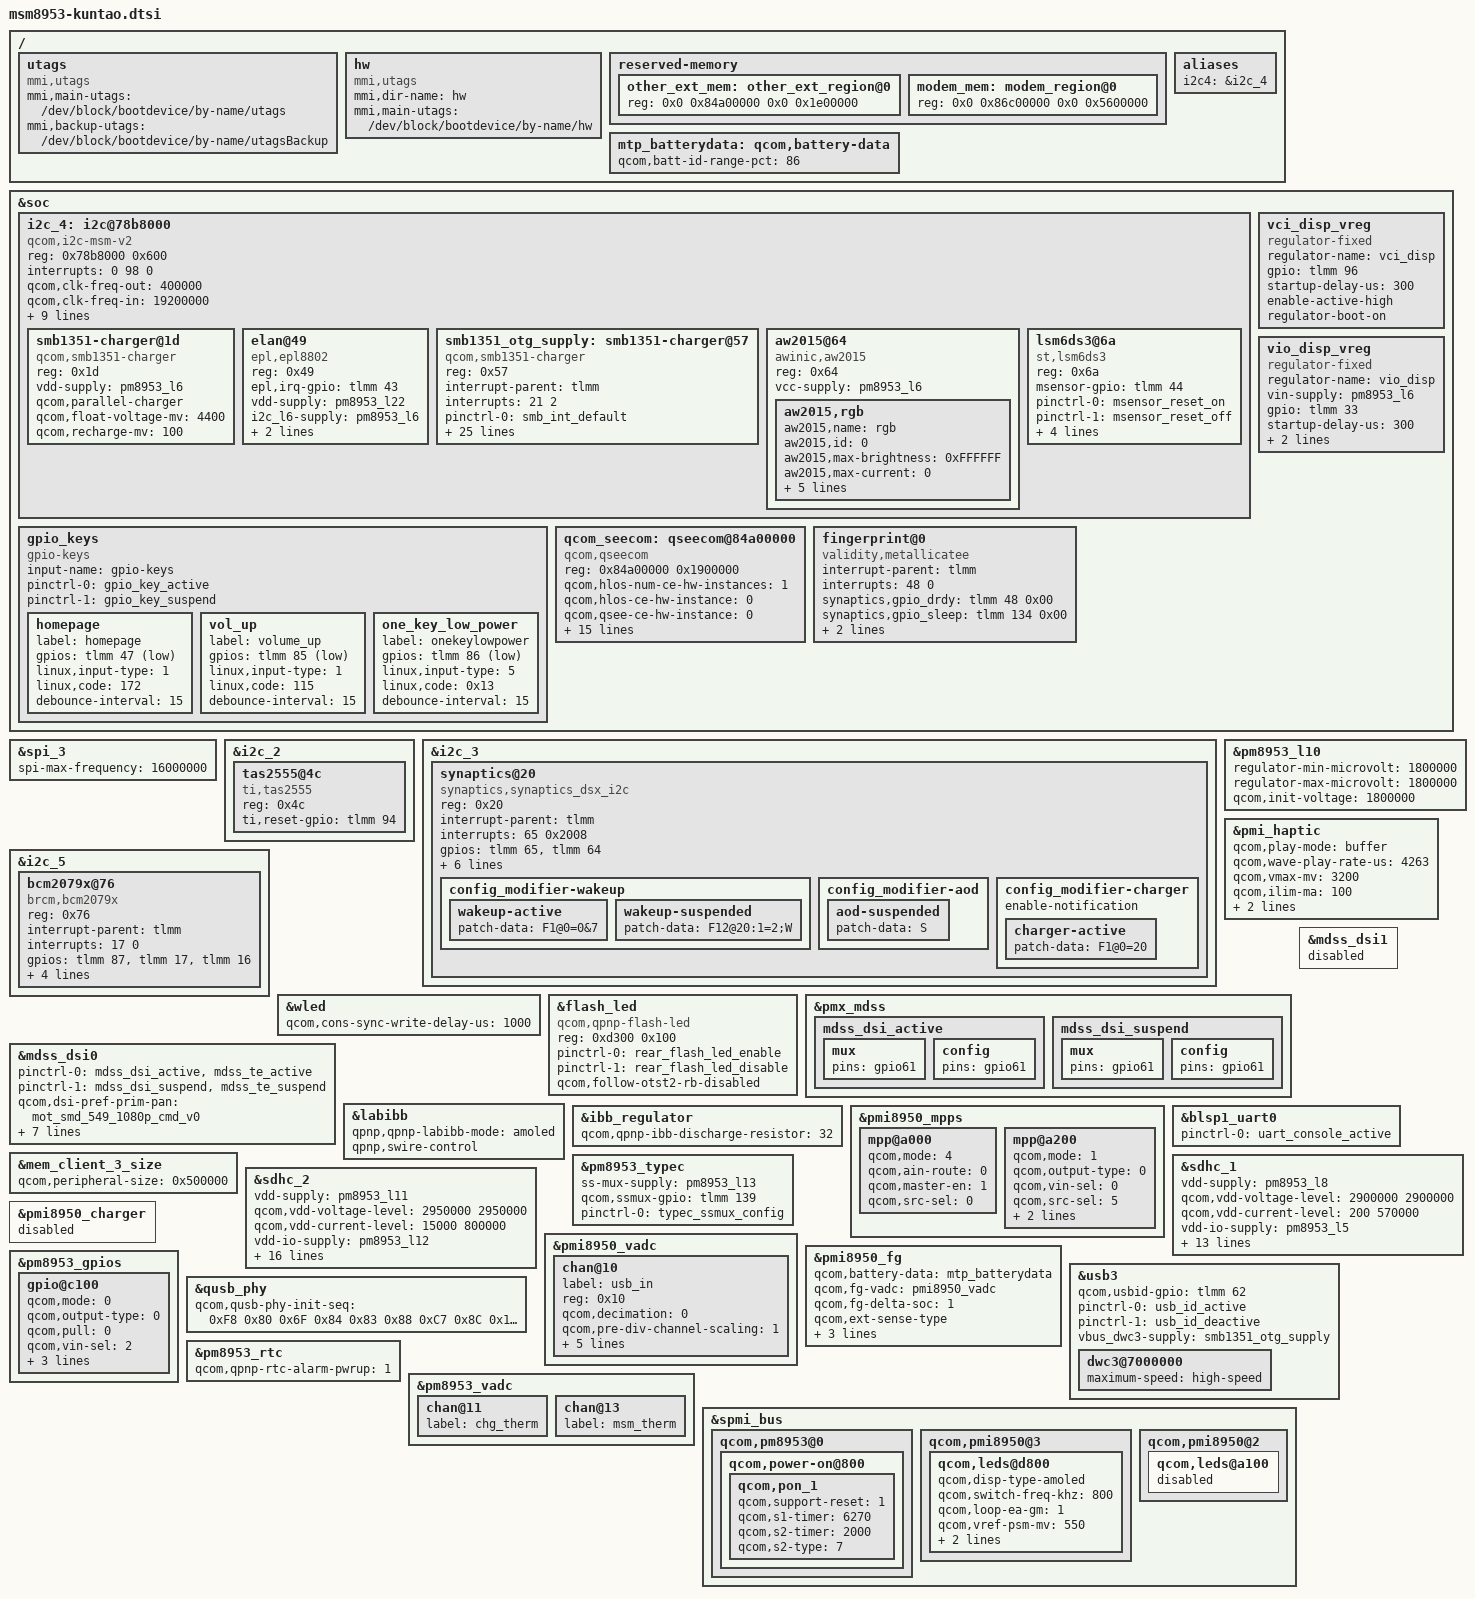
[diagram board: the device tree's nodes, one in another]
/*
 * Copyright (c) 2015-2016, The Linux Foundation. All rights reserved.
 * Copyright (c) 2015, Motorola Mobility Inc. All rights reserved.
 *
 * This program is free software; you can redistribute it and/or modify
 * it under the terms of the GNU General Public License version 2 and
 * only version 2 as published by the Free Software Foundation.
 *
 * This program is distributed in the hope that it will be useful,
 * but WITHOUT ANY WARRANTY; without even the implied warranty of
 * MERCHANTABILITY or FITNESS FOR A PARTICULAR PURPOSE.  See the
 * GNU General Public License for more details.
 */

#include "msm8953-pinctrl-kuntao.dtsi"
#include "msm8953-audio-kuntao.dtsi"
#include "msm8953-camera-sensor-kuntao.dtsi"

/ {
	utags {
		compatible = "mmi,utags";
		mmi,main-utags = "/dev/block/bootdevice/by-name/utags";
		mmi,backup-utags = "/dev/block/bootdevice/by-name/utagsBackup";
	};

	hw {
		compatible = "mmi,utags";
		mmi,dir-name = "hw";
		mmi,main-utags = "/dev/block/bootdevice/by-name/hw";
	};

	reserved-memory {
		other_ext_mem: other_ext_region@0 {
			reg = <0x0 0x84a00000 0x0 0x1e00000>;
		};

		modem_mem: modem_region@0 {
			reg = <0x0 0x86c00000 0x0 0x5600000>;
		};
	};

	aliases {
		i2c4 = &i2c_4;
	};
};

&soc {
	i2c_4: i2c@78b8000 { /* BLSP1 QUP4 */
		compatible = "qcom,i2c-msm-v2";
		#address-cells = <1>;
		#size-cells = <0>;
		reg-names = "qup_phys_addr";
		reg = <0x78b8000 0x600>;
		interrupt-names = "qup_irq";
		interrupts = <0 98 0>;
		qcom,clk-freq-out = <400000>;
		qcom,clk-freq-in  = <19200000>;
		clock-names = "iface_clk", "core_clk";
		clocks = <&clock_gcc clk_gcc_blsp1_ahb_clk>,
			 <&clock_gcc clk_gcc_blsp1_qup4_i2c_apps_clk>;

		pinctrl-names = "i2c_active", "i2c_sleep";
		pinctrl-0 = <&i2c_4_active>;
		pinctrl-1 = <&i2c_4_sleep>;
		qcom,noise-rjct-scl = <0>;
		qcom,noise-rjct-sda = <0>;
		qcom,master-id = <86>;
		dmas = <&dma_blsp1 10 64 0x20000020 0x20>,
			<&dma_blsp1 11 32 0x20000020 0x20>;
		dma-names = "tx", "rx";
	};
};

&spi_3 { /* BLSP1 QUP3 */
	spi-max-frequency = <16000000>;
};

&i2c_2 {
	tas2555@4c {
		compatible = "ti,tas2555";
		reg = <0x4c>;
		ti,reset-gpio = <&tlmm 94 0>;
	};
};

&i2c_3 { /* BLSP1 QUP3 */
	status = "okay";
	synaptics@20 {
		compatible = "synaptics,synaptics_dsx_i2c";
		reg = <0x20>;
		interrupt-parent = <&tlmm>;
		interrupts = <65 0x2008>;
		gpios = <&tlmm 65 0x2008>, /* IRQ */
			<&tlmm 64 0>; /* RESET */
		synaptics,gpio-config;
		pinctrl-names = "default", "active";
		pinctrl-0 = <&touch_reset_active &touch_int_default>;
		pinctrl-1 = <&touch_reset_active &touch_int_active>;

		config_modifier-names = "wakeup", "aod", "charger";
		config_modifier-wakeup {
			wakeup-active {
				patch-data = "F1@0=0&7";
			};

			wakeup-suspended {
				patch-data = "F12@20:1=2;W";
			};
		};

		config_modifier-aod {
			aod-suspended {
				patch-data = "S"; /* Power->sleep */
			};
		};

		config_modifier-charger {
			enable-notification;
			charger-active {
				/* Charger bit; */
				patch-data = "F1@0=20";
			};
		};
	};
};

&i2c_4 {
	smb1351-charger@1d {
		compatible = "qcom,smb1351-charger";
		status = "okay";
		reg = <0x1d>;
		vdd-supply = <&pm8953_l6>;
		qcom,parallel-charger;
		qcom,float-voltage-mv = <4400>;
		qcom,recharge-mv = <100>;
	};

	elan@49 {
		compatible = "epl,epl8802";
		reg = <0x49>;
		epl,irq-gpio = <&tlmm 43 0x08>;
		vdd-supply = <&pm8953_l22>;
		i2c_l6-supply = <&pm8953_l6>;
		pinctrl-names = "epl8802_default", "epl8802_suspend";
		pinctrl-0 = <&epl8802_active>;
		pinctrl-1 = <&epl8802_suspend>;
	};

	smb1351_otg_supply: smb1351-charger@57 {
		compatible = "qcom,smb1351-charger";
		reg = <0x57>;
		status = "okay";
		interrupt-parent = <&tlmm>;
		interrupts = <21 2>;
		pinctrl-names = "default";
		pinctrl-0 = <&smb_int_default>;
		vdd-supply = <&pm8953_l6>;
		qcom,chg-pm-vadc = <&pm8953_vadc>;
		qcom,chg-pmi-vadc = <&pmi8950_vadc>;
		qcom,en-gpio = <&tlmm 20 0x0>;
		qcom,otg-short-gpio = <&tlmm 13 0x0>;
		qcom,float-voltage-mv = <4400>;
		qcom,fastchg-current-max-ma = <2000>;
		qcom,iterm-ma = <200>;
		qcom,recharge-mv = <100>;
		regulator-name = "smb1351_otg_vreg";
		qcom,bms-psy-name = "bms";
		qcom,bms-hw-is-fg;
		qcom,batt-hot-decidegc = <500>;
		qcom,batt-cold-decidegc = <0>;
		qcom,batt-missing-decidegc = <(-200)>;
		qcom,batt-warm-decidegc = <460>;
		qcom,batt-cool-decidegc = <100>;
		qcom,batt-warm-mv = <4200>;
		qcom,batt-cool-mv = <4400>;
		qcom,parallel-usb-min-current-ma = <1500>;
		qcom,parallel-usb-9v-min-current-ma = <1500>;
		qcom,parallel-usb-12v-min-current-ma = <1500>;
		qcom,parallel-allowed-lowering-ma = <1500>;
		qcom,use-external-fg;
		qcom,resume-soc = <96>;
	};

	aw2015@64 {
		status = "ok";
		compatible = "awinic,aw2015";
		reg = <0x64>;
		vcc-supply = <&pm8953_l6>;

		aw2015,rgb {
			aw2015,name = "rgb";
			aw2015,id = <0>;
			aw2015,max-brightness = <0xFFFFFF>;
			aw2015,max-current = <0>; /*0:3mA 1:6.375mA 2:12.75mA 3:25.5mA*/
			aw2015,rise-time-ms = <4>;
			aw2015,hold-time-ms = <4>;
			aw2015,fall-time-ms = <4>;
			aw2015,off-time-ms = <7>;
			aw2015,pwm-duty = <255>; /*127/255 = 50%*/
		};
	};

	lsm6ds3@6a {
		compatible = "st,lsm6ds3";
		reg = <0x6a>;
		msensor-gpio = <&tlmm 44 0x0>;
		pinctrl-names = "msensor_reset_on", "msensor_reset_off";
		pinctrl-0 = <&msensor_reset_on>;
		pinctrl-1 = <&msensor_reset_off>;
		vdd-supply = <&pm8953_l22>;
		vio-supply = <&pm8953_l6>;
		interrupt-parent = <&tlmm>;
		interrupts = <42 0x02>;
	};
};

&i2c_5 { /* BLSP2 QUP1 (NFC) */
	/* BCM 20797 NFC Controller */
	bcm2079x@76 {
		status = "ok";
		compatible = "brcm,bcm2079x";
		reg = <0x76>;
		interrupt-parent = <&tlmm>;
		interrupts = <17 0>;	/* NFC_IRQ */
		gpios = <&tlmm 87 0>,	/* NFC_ENABLE_IN */
			<&tlmm 17 0>,	/* NFC_IRQ */
			<&tlmm 16 0>;	/* NFC_POWER_ON */

		pinctrl-names = "default";
		pinctrl-0 = <&nfc_irq_default &nfc_pwr_default &nfc_en_default>;

		qcom,clk-gpio = <&pm8953_gpios 2 0x00>;
		clocks = <&clock_gcc clk_bb_clk2_pin>;
		clock-names = "ref_clk";
	};
};

&pm8953_l10 {
	regulator-min-microvolt = <1800000>;
	regulator-max-microvolt = <1800000>;
	qcom,init-voltage = <1800000>;
};

&soc {
	gpio_keys {
		compatible = "gpio-keys";
		input-name = "gpio-keys";
		pinctrl-names = "tlmm_gpio_key_active", "tlmm_gpio_key_suspend";
		pinctrl-0 = <&gpio_key_active>;
		pinctrl-1 = <&gpio_key_suspend>;

		homepage {
			label = "homepage";
			gpios = <&tlmm 47 0x1>;
			linux,input-type = <1>;
			linux,code = <172>;
			debounce-interval = <15>;
		};

		vol_up {
			label = "volume_up";
			gpios = <&tlmm 85 0x1>;
			linux,input-type = <1>;
			linux,code = <115>;
			debounce-interval = <15>;
		};

		one_key_low_power {
			label = "onekeylowpower";
			gpios = <&tlmm 86 0x1>;
			linux,input-type = <5>;
			linux,code = <0x13>;
			debounce-interval = <15>;
		};
	};

	/delete-node/ qseecom@85b00000;

	qcom_seecom: qseecom@84a00000 {
		compatible = "qcom,qseecom";
		reg = <0x84a00000 0x1900000>;
		reg-names = "secapp-region";
		qcom,hlos-num-ce-hw-instances = <1>;
		qcom,hlos-ce-hw-instance = <0>;
		qcom,qsee-ce-hw-instance = <0>;
		qcom,disk-encrypt-pipe-pair = <2>;
		qcom,support-fde;
		qcom,msm-bus,name = "qseecom-noc";
		qcom,msm-bus,num-cases = <4>;
		qcom,msm-bus,num-paths = <1>;
		qcom,support-bus-scaling;
		qcom,appsbl-qseecom-support;
		qcom,msm-bus,vectors-KBps =
			<55 512 0 0>,
			<55 512 0 0>,
			<55 512 120000 1200000>,
			<55 512 393600 3936000>;
		clocks = <&clock_gcc clk_crypto_clk_src>,
			 <&clock_gcc clk_gcc_crypto_clk>,
			 <&clock_gcc clk_gcc_crypto_ahb_clk>,
			 <&clock_gcc clk_gcc_crypto_axi_clk>;
		clock-names = "core_clk_src", "core_clk",
				"iface_clk", "bus_clk";
		qcom,ce-opp-freq = <100000000>;
	};

	vci_disp_vreg: vci_disp_vreg {
		compatible = "regulator-fixed";
		regulator-name = "vci_disp";
		gpio = <&tlmm 96 0>;
		startup-delay-us = <300>;
		enable-active-high;
		regulator-boot-on;
	};

	vio_disp_vreg: vio_disp_vreg {
		compatible = "regulator-fixed";
		regulator-name = "vio_disp";
		vin-supply = <&pm8953_l6>;
		gpio = <&tlmm 33 0>;
		startup-delay-us = <300>;
		enable-active-high;
		regulator-boot-on;
	};

	fingerprint@0 {
		compatible = "validity,metallicatee";
		interrupt-parent = <&tlmm>;
		interrupts = <48 0>;
		synaptics,gpio_drdy = <&tlmm 48 0x00>;
		synaptics,gpio_sleep = <&tlmm 134 0x00>;
		synaptics,gpio_3p3v = <&tlmm 139 0x00>;
		synaptics,gpio_1p8v = <&tlmm 63 0x00>;
	};
};

&pmi_haptic {
	qcom,play-mode = "buffer";
	qcom,wave-play-rate-us = <4263>;
	qcom,vmax-mv = <3200>;
	qcom,ilim-ma = <100>;
	qcom,brake-pattern = [03 02 00 00];
	qcom,wave-samples = [5c 5c 5c 5c 5c 5c 5c 5c];
};

&wled {
	qcom,cons-sync-write-delay-us = <1000>;
};

&flash_led {
	compatible = "qcom,qpnp-flash-led";
	reg = <0xd300 0x100>;
	pinctrl-names = "flash_led_enable", "flash_led_disable";
	pinctrl-0 = <&rear_flash_led_enable>;
	pinctrl-1 = <&rear_flash_led_disable>;
	qcom,follow-otst2-rb-disabled;
};

#include "dsi-panel-mot-smd-549-1080p-cmd.dtsi"

&pmx_mdss {
	mdss_dsi_active {
		mux {
			pins = "gpio61";
		};

		config {
			pins = "gpio61";
		};
	};

	mdss_dsi_suspend {
		mux {
			pins = "gpio61";
		};

		config {
			pins = "gpio61";
		};
	};
};

&mdss_dsi0 {
	pinctrl-names = "mdss_default", "mdss_sleep";
	pinctrl-0 = <&mdss_dsi_active &mdss_te_active>;
	pinctrl-1 = <&mdss_dsi_suspend &mdss_te_suspend>;

	qcom,dsi-pref-prim-pan = <&mot_smd_549_1080p_cmd_v0>;
	vci_disp-supply = <&vci_disp_vreg>;
	vio_disp-supply = <&vio_disp_vreg>;
	elvdd_disp-supply = <&lab_regulator>;
	elvss_disp-supply = <&ibb_regulator>;
	qcom,platform-reset-gpio = <&tlmm 61 0>;
	qcom,platform-te-gpio = <&tlmm 24 0>;
	qcom,display-id = "primary";
};

&mdss_dsi1 {
	status = "disabled";
};

&labibb {
	status = "ok";
	qpnp,qpnp-labibb-mode = "amoled";
	qpnp,swire-control;
};

&ibb_regulator {
	qcom,qpnp-ibb-discharge-resistor = <32>;
};

&pmi8950_mpps {
	mpp@a000 {
		/* Host detect */
		status = "ok";
		qcom,mode = <4>; /* AIN input */
		qcom,ain-route = <0>; /* AMUX 5 */
		qcom,master-en = <1>;
		qcom,src-sel = <0>; /* Function constant */
	};

	mpp@a200 {
		qcom,mode = <1>;		/* Digital output */
		qcom,output-type = <0>;		/* CMOS logic */
		qcom,vin-sel = <0>;
		qcom,src-sel = <5>;		/* DTEST2 */
		qcom,master-en = <1>;		/* Enable GPIO */
		qcom,invert = <0>;
		status = "okay";
	};
};

&blsp1_uart0 {
	status = "ok";
	pinctrl-names = "default";
	pinctrl-0 = <&uart_console_active>;
};

&mem_client_3_size {
	qcom,peripheral-size = <0x500000>;
};

&sdhc_1 {
	/* device core power supply */
	vdd-supply = <&pm8953_l8>;
	qcom,vdd-voltage-level = <2900000 2900000>;
	qcom,vdd-current-level = <200 570000>;

	/* device communication power supply */
	vdd-io-supply = <&pm8953_l5>;
	qcom,vdd-io-always-on;
	qcom,vdd-io-lpm-sup;
	qcom,vdd-io-voltage-level = <1800000 1800000>;
	qcom,vdd-io-current-level = <200 325000>;

	pinctrl-names = "active", "sleep";
	pinctrl-0 = <&sdc1_clk_on &sdc1_cmd_on &sdc1_data_on  &sdc1_rclk_on>;
	pinctrl-1 = <&sdc1_clk_off &sdc1_cmd_off &sdc1_data_off &sdc1_rclk_off>;

	qcom,clk-rates = <400000 20000000 25000000 50000000 100000000 192000000
								384000000>;
	qcom,nonremovable;
	qcom,bus-speed-mode = "HS400_1p8v", "HS200_1p8v", "DDR_1p8v";

	status = "ok";
};

&sdhc_2 {
	/* device core power supply */
	vdd-supply = <&pm8953_l11>;
	qcom,vdd-voltage-level = <2950000 2950000>;
	qcom,vdd-current-level = <15000 800000>;

	/* device communication power supply */
	vdd-io-supply = <&pm8953_l12>;
	qcom,vdd-io-voltage-level = <1800000 2950000>;
	qcom,vdd-io-current-level = <200 22000>;

	pinctrl-names = "active", "sleep";
	pinctrl-0 = <&sdc2_clk_on &sdc2_cmd_on &sdc2_data_on &sdc2_cd_on>;
	pinctrl-1 = <&sdc2_clk_off &sdc2_cmd_off &sdc2_data_off>;

	#address-cells = <0>;
	interrupt-parent = <&sdhc_2>;
	interrupts = <0 1 2>;
	#interrupt-cells = <1>;
	interrupt-map-mask = <0xffffffff>;
	interrupt-map = <0 &intc 0 125 0
		1 &intc 0 221 0
		2 &tlmm 133 0>;
	interrupt-names = "hc_irq", "pwr_irq", "status_irq";
	cd-gpios = <&tlmm 133 0x0>;

	qcom,clk-rates = <400000 20000000 25000000 50000000 100000000
								200000000>;
	qcom,bus-speed-mode = "SDR12", "SDR25", "SDR50", "DDR50", "SDR104";

	status = "ok";
};

&pm8953_typec {
	ss-mux-supply = <&pm8953_l13>;
	qcom,ssmux-gpio = <&tlmm 139 GPIO_ACTIVE_HIGH>;
	pinctrl-names = "default";
	pinctrl-0 = <&typec_ssmux_config>;
};

/ {
	mtp_batterydata: qcom,battery-data {
		qcom,batt-id-range-pct = <86>;
		#include "batterydata-kuntao-5000mah.dtsi"
		#include "batterydata-kuntao-2-5000mah.dtsi"
	};
};

&pmi8950_vadc {
	chan@10 {
		label = "usb_in";
		reg = <0x10>;
		qcom,decimation = <0>;
		qcom,pre-div-channel-scaling = <1>;
		qcom,calibration-type = "absolute";
		qcom,scale-function = <0>;
		qcom,hw-settle-time = <0>;
		qcom,fast-avg-setup = <0>;
		qcom,vadc-thermal-node;
	};
};

&pmi8950_fg {
	qcom,battery-data = <&mtp_batterydata>;
	qcom,fg-vadc = <&pmi8950_vadc>;
	qcom,fg-delta-soc = <1>;
	qcom,ext-sense-type;
	qcom,vbat-estimate-diff-mv= <100>;
	qcom,fg-iterm-ma = <600>;
	qcom,hold-soc-while-full;
};

&pmi8950_charger {
	status = "disabled";
};

&pm8953_gpios {
	/* GPIO 2 (NFC_CLK_REQ) */
	gpio@c100 {
		qcom,mode = <0>;
		qcom,output-type = <0>;
		qcom,pull = <0>;
		qcom,vin-sel = <2>;
		qcom,out-strength = <3>;
		qcom,src-sel = <0>;
		qcom,master-en = <1>;
		status = "okay";
	};
};

&usb3 {
	qcom,usbid-gpio = <&tlmm 62 0>;
	pinctrl-names = "usbid_default", "usbid_deactive";
	pinctrl-0 = <&usb_id_active>;
	pinctrl-1 = <&usb_id_deactive>;
	vbus_dwc3-supply = <&smb1351_otg_supply>;

	dwc3@7000000 {
		maximum-speed = "high-speed";
	};
};

&qusb_phy {
	qcom,qusb-phy-init-seq = <0xF8 0x80
				0x6F 0x84
				0x83 0x88
				0xC7 0x8C
				0x14 0x9C
				0x30 0x08
				0x79 0x0C
				0x21 0x10
				0x03 0x90
				0x9F 0x1C
				0x00 0x18>;
};

&pm8953_rtc {
	qcom,qpnp-rtc-alarm-pwrup = <1>;
};

&pm8953_vadc {
	chan@11 {
		label = "chg_therm";
	};

	chan@13 {
		label = "msm_therm";
	};
};

&spmi_bus {
	qcom,pm8953@0 {
		qcom,power-on@800 {
			qcom,pon_1 {
				qcom,support-reset = <1>;
				qcom,s1-timer = <6270>;
				qcom,s2-timer = <2000>;
				qcom,s2-type = <7>;
			};
		};
	};

	qcom,pmi8950@3 {
		qcom,leds@d800 {
			qcom,disp-type-amoled;
			qcom,switch-freq-khz = <800>;
			qcom,loop-ea-gm = <1>;
			qcom,vref-psm-mv = <550>;
			qcom,ovp-mv = <31000>;
			qcom,enable-amoled-pulse-skipping;
		};
	};

	qcom,pmi8950@2 {
		qcom,leds@a100 {
			status = "disabled";
		};
	};
};
